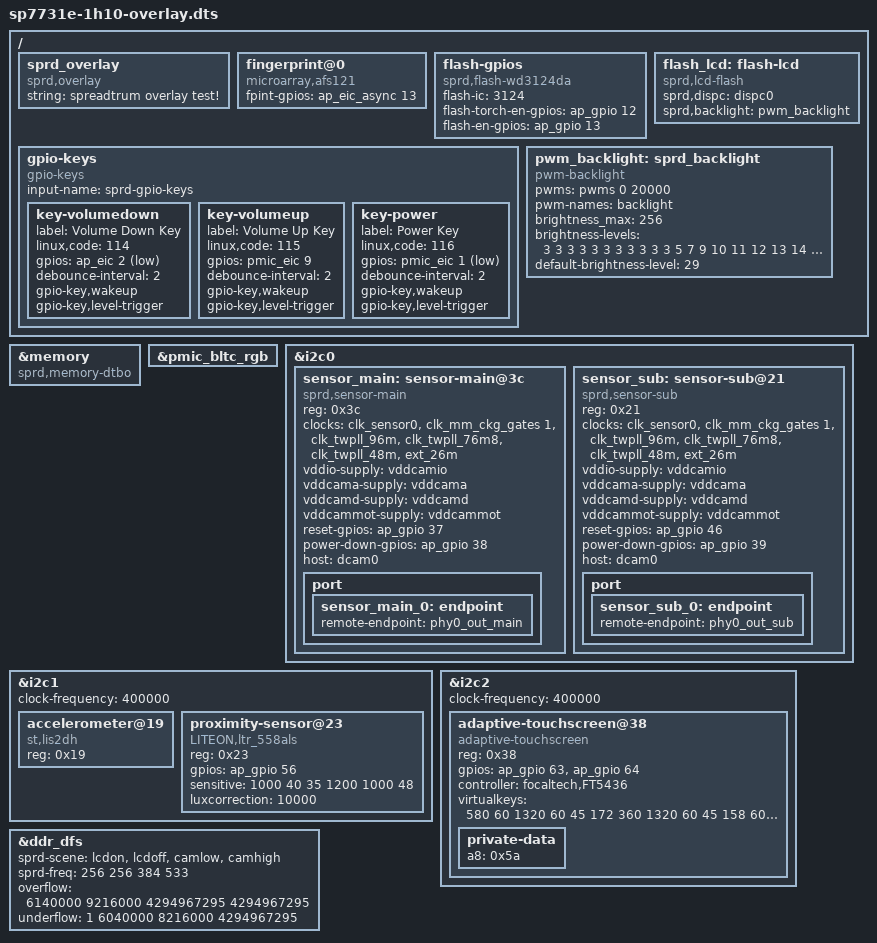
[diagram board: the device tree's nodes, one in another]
/*
 * Spreadtrum sharkle sp7731e board DTS file
 *
 * Copyright (C) 2018, Spreadtrum Communications Inc.
 *
 * This file is licensed under a dual GPLv2 or X11 license.
 */
/dts-v1/;
/plugin/;

/ {
	/*
	* When create a new node, we should use the key word __overlay__,
	* otherwise u-boot can not analyze it.
	*/

	fragment {
		target-path = "/";
		__overlay__ {
			sprd_overlay {
				compatible = "sprd,overlay";
				string = "spreadtrum overlay test!";
			};

			fingerprint@0 {
				compatible = "microarray,afs121";
				fpint-gpios = <&ap_eic_async 13 0>;
			};

			flash-gpios {
				compatible = "sprd,flash-wd3124da";
				flash-ic = <3124>;
				flash-torch-en-gpios = <&ap_gpio 12 0>;
				flash-en-gpios = <&ap_gpio 13 0>;
			};

			flash_lcd: flash-lcd {
				compatible = "sprd,lcd-flash";
				sprd,dispc = <&dispc0>;
				sprd,backlight = <&pwm_backlight>;
				status = "okay";
			};

			gpio-keys {
				compatible = "gpio-keys";
				input-name = "sprd-gpio-keys";
				status = "okay";

				key-volumedown {
					label = "Volume Down Key";
					linux,code = <114>;
					gpios = <&ap_eic 2 1>;
					debounce-interval = <2>;
					gpio-key,wakeup;
					gpio-key,level-trigger;
				};

				key-volumeup {
					label = "Volume Up Key";
					linux,code = <115>;
					gpios = <&pmic_eic 9 0>;
					debounce-interval = <2>;
					gpio-key,wakeup;
					gpio-key,level-trigger;
				};

				key-power {
					label = "Power Key";
					linux,code = <116>;
					gpios = <&pmic_eic 1 1>;
					debounce-interval = <2>;
					gpio-key,wakeup;
					gpio-key,level-trigger;
				};
			};
			pwm_backlight: sprd_backlight {
				compatible = "pwm-backlight";
				pwms = <&pwms 0 20000>;
				pwm-names = "backlight";
				brightness_max = <256>;
				brightness-levels = <
								  3   3   3   3
					  3   3   3   3   3   3   3   5   7   9
					 10  11  12  13  14  15  16  17  18  19
					 20  21  22  23  24  25  26  27  28  29
					 30  31  32  33  34  35  36  37  38  39
					 40  41  42  43  44  45  46  47  48  49
					 50  51  52  53  54  55  56  57  58  59
					 60  61  62  63  64  65  66  67  68  69
					 70  71  72  73  74  75  76  77  78  79
					 80  81  82  83  84  85  86  87  88  89
					 90  91  92  93  94  95  96  97  98  99
					100 101 102 103 104 105 106 107 108 109
					110 111 112 113 114 115 116 117 118 119
					120 121 122 123 124 125 126 127 128 129
					130 131 132 133 134 135 136 137 138 139
					140 141 142 143 144 145 146 147 148 149
					150 151 152 153 154 155 156 157 158 159
					160 161 162 163 164 165 166 167 168 169
					170 171 172 173 174 175 176 177 178 179
					180 181 182 183 184 185 186 187 188 189
					190 191 192 193 194 195 196 197 198 199
					200 201 202 203 204 205 206 207 208 209
					210 211 212 213 214 215 216 217 218 219
					220 221 222 223 224 225 226 227 228 229
					230 231 232 233 234 235 236 237 238 239
					240 241 242 243 244 245 246 247 248 249
					250 251
					>;
				default-brightness-level = <29>;
			};
		};
	};
};

/*
 * Sample code. Google strongly recommends you do not use fragment@x and
 * syntax __overlay__, and instead use the reference syntax
*/
&memory {
	compatible = "sprd,memory-dtbo";
};

&pmic_bltc_rgb {
	status = "okay";
};

&i2c0 {
	sensor_main: sensor-main@3c {
		compatible = "sprd,sensor-main";
		reg = <0x3c>;
		clock-names = "clk_src", "sensor_eb",
			"clk_96m", "clk_76m8",
			"clk_48m", "clk_26m";
		clocks  = <&clk_sensor0>,
			<&clk_mm_ckg_gates 1>,
			<&clk_twpll_96m>,
			<&clk_twpll_76m8>,
			<&clk_twpll_48m>,
			<&ext_26m>;
		vddio-supply = <&vddcamio>;
		vddcama-supply = <&vddcama>;
		vddcamd-supply = <&vddcamd>;
		vddcammot-supply = <&vddcammot>;
		reset-gpios = <&ap_gpio 37 0>;
		power-down-gpios = <&ap_gpio 38 0>;
		host = "dcam0";
		port {
			sensor_main_0: endpoint {
				remote-endpoint = <&phy0_out_main>;
			};
		};
	};

	sensor_sub: sensor-sub@21 {
		compatible = "sprd,sensor-sub";
		reg = <0x21>;
		clock-names = "clk_src","sensor_eb",
			"clk_96m", "clk_76m8",
			"clk_48m", "clk_26m";
		clocks = <&clk_sensor0>,
			<&clk_mm_ckg_gates 1>,
			<&clk_twpll_96m>,
			<&clk_twpll_76m8>,
			<&clk_twpll_48m>,
			<&ext_26m>;
		vddio-supply = <&vddcamio>;
		vddcama-supply = <&vddcama>;
		vddcamd-supply = <&vddcamd>;
		vddcammot-supply = <&vddcammot>;
		reset-gpios = <&ap_gpio 46 0>;
		power-down-gpios = <&ap_gpio 39 0>;
		host = "dcam0";
		port {
			sensor_sub_0: endpoint {
				remote-endpoint = <&phy0_out_sub>;
			};
		};
	};
};

&i2c1 {
	status = "okay";
	clock-frequency = <400000>;

	accelerometer@19 {
		compatible = "st,lis2dh", "st,lis2dh12";
		reg = <0x19>;
	};

	proximity-sensor@23 {
		compatible = "LITEON,ltr_558als";
		reg = <0x23>;
		gpios = <&ap_gpio 56 0>;
		/*
		 *low sensitve(def):1500,250,220,1800,1600,1;
		 *have no sensitve=<> as def.
		 * High sensitve:1000,40,35,1200,1000,48
		 */
		sensitive = <1000 40 35
					1200 1000 48>;
		luxcorrection = <10000>;
	};
};

&i2c2 {
	status = "okay";
	clock-frequency = <400000>;
	adaptive-touchscreen@38 {
		compatible = "adaptive-touchscreen";
		reg = <0x38>;
		gpios = <&ap_gpio 63 0
			&ap_gpio 64 0>;
		controller = "focaltech,FT5436";
		virtualkeys = <580 60 1320 60 45
			172 360 1320 60 45
			158 600 1320 60 45>;
		private-data {
			a8 = /bits/ 8 <0x5a>;
		};
	};
};

&ddr_dfs {
	sprd-scene = "lcdon", "lcdoff", "camlow", "camhigh";
	sprd-freq = <256 256 384 533>;
	overflow = <6140000 9216000 4294967295 4294967295>;
	underflow = <1 6040000 8216000 4294967295>;
};
